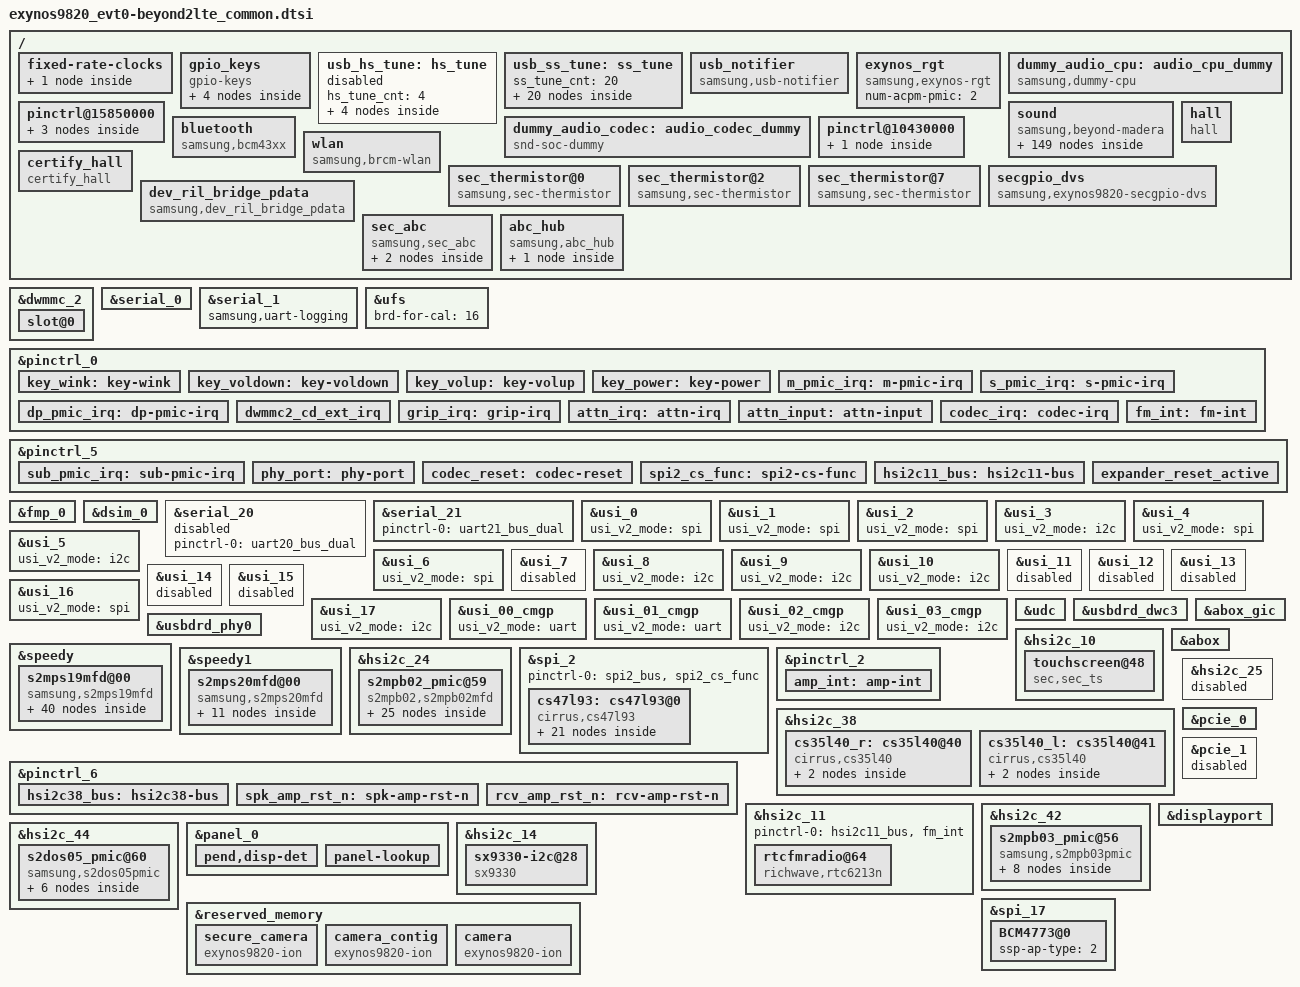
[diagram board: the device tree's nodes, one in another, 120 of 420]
/*
 * SAMSUNG EXYNOS9820 board device tree source
 *
 * Copyright (c) 2018 Samsung Electronics Co., Ltd.
 *		http://www.samsung.com
 *
 * This program is free software; you can redistribute it and/or modify
 * it under the terms of the GNU General Public License version 2 as
 * published by the Free Software Foundation.
*/
#include "exynos9820-beyond2lte_mst.dtsi"
#include "modem-s5000ap-sipc-pdata.dtsi"

/ {

	fragment@model {
		target-path = "/";
		__overlay__ {
			#address-cells = <2>;
			#size-cells = <1>;

			fixed-rate-clocks {
				oscclk {
					compatible = "samsung,exynos9820-oscclk";
					clock-frequency = <26000000>;
				};
			};

			gpio_keys {
				status = "okay";
				compatible = "gpio-keys";
				pinctrl-names = "default";
				pinctrl-0 = <&key_wink &key_voldown &key_volup &key_power>;
				button@1 {
					label = "gpio-keys: KEY_WINK";
					linux,code = <703>;
					gpios = <&gpa0 6 0xf>;
					gpio-key,wakeup = <1>;
				};
				button@2 {
					label = "gpio-keys: KEY_VOLUMEDOWN";
					linux,code = <114>;
					gpios = <&gpa0 4 0xf>;
				};
				button@3 {
					label = "gpio-keys: KEY_VOLUMEUP";
					linux,code = <115>;
					gpios = <&gpa0 3 0xf>;
				};
				button@4 {
					label = "gpio-keys: KEY_POWER";
					linux,code = <116>;
					gpios = <&gpa2 4 0xf>;
					gpio-key,wakeup = <1>;
				};
			};

			usb_hs_tune:hs_tune {
				status = "disabled";
				hs_tune_cnt = <4>;
				/* value = <device host> */
				hs_tune1 {
					tune_name = "tx_pre_emp";
					tune_value = <0x3 0x3>;
				};

				hs_tune2 {
					tune_name = "tx_vref";
					tune_value = <0xc 0xc>;
				};

				hs_tune3 {
					tune_name = "rx_sqrx";
					tune_value = <0x5 0x5>;
				};

				hs_tune4 {
					tune_name = "utmi_clk";
					tune_value = <0x1 0x1>;
				};
			};

			usb_ss_tune:ss_tune {
				status = "okay";
				ss_tune_cnt = <20>;
				/* value = <device host> */
				ss_tune1 {
					tune_name = "ssrx_sqhs_th";
					tune_value = <0x4 0x4>;
				};

				ss_tune2 {
					tune_name = "ssrx_lfps_th";
					tune_value = <0x2 0x2>;
				};

				ss_tune3 {
					tune_name = "ssrx_mf_eq_en";
					tune_value = <0x1 0x1>;
				};

				ss_tune4 {
					tune_name = "ssrx_mf_eq_ctrl_ss";
					tune_value = <0x6 0x6>;
				};

				ss_tune5 {
					tune_name = "ssrx_hf_eq_ctrl_ss";
					tune_value = <0xc 0xe>;
				};

				ss_tune6 {
					tune_name = "ssrx_mf_eq_ctrl_ssp";
					tune_value = <0x6 0x6>;
				};

				ss_tune7 {
					tune_name = "ssrx_hf_eq_ctrl_ssp";
					tune_value = <0xe 0xe>;
				};

				ss_tune8 {
					tune_name = "ssrx_dfe1_tap_ctrl";
					tune_value = <0x0 0x2>;
				};

				ss_tune9 {
					tune_name = "ssrx_dfe2_tap_ctrl";
					tune_value = <0x0 0x0>;
				};

				ss_tune10 {
					tune_name = "ssrx_dfe3_tap_ctrl";
					tune_value = <0x0 0x0>;
				};

				ss_tune11 {
					tune_name = "ssrx_dfe4_tap_ctrl";
					tune_value = <0x0 0x0>;
				};

				ss_tune12 {
					tune_name = "ssrx_dfe5_tap_ctrl";
					tune_value = <0x0 0x0>;
				};

				ss_tune13 {
					tune_name = "ssrx_term_cal";
					tune_value = <0xb 0xb>;
				};

				ss_tune14 {
					tune_name = "sstx_amp";
					tune_value = <0xb 0xb>;
				};

				ss_tune15 {
					tune_name = "sstx_deemp";
					tune_value = <0x5 0x5>;
				};

				ss_tune16 {
					tune_name = "sstx_pre_shoot";
					tune_value = <0x3 0x3>;
				};

				ss_tune17 {
					tune_name = "sstx_idrv_up";
					tune_value = <0x7 0x7>;
				};

				ss_tune18 {
					tune_name = "sstx_idrv_dn";
					tune_value = <0x0 0x0>;
				};

				ss_tune19 {
					tune_name = "sstx_up_term";
					tune_value = <0x3 0x3>;
				};

				ss_tune20 {
					tune_name = "sstx_dn_term";
					tune_value = <0x3 0x3>;
				};
			};

			usb_notifier {
				compatible = "samsung,usb-notifier";
				/*
				 * USB_LDOCONTROL_EXYNOS8895	1
				 * USB_LDOCONTROL_EXYNOS9810	2
				 * USB_LDOCONTROL_EXYNOS9820	3
				 */
				usb-ldocontrol = <3>;
				udc = <&udc>;
				disable_host_wakelock;
			};

			exynos_rgt {
				compatible = "samsung,exynos-rgt";
				num-acpm-pmic = <2>;
			};

			dummy_audio_codec: audio_codec_dummy {
				status = "okay";
				compatible = "snd-soc-dummy";
			};

			dummy_audio_cpu: audio_cpu_dummy {
				compatible = "samsung,dummy-cpu";
				status = "okay";
			};

			sound {
				status = "okay";
				compatible = "samsung,beyond-madera";

				clock-names = "xclkout";
				clocks = <&clock OSC_AUD>;

				cirrus,sysclk = <1 4 98304000>;
				cirrus,asyncclk = <2 5 98304000>;
				cirrus,dspclk = <8 4 147456000>;
				cirrus,outclk = <9 1 0>;
				cirrus,fll1-refclk = <1 0 26000000>;
				cirrus,fll2-refclk = <2 8 26000000>;

				cirrus,ampclk = <0 0 6144000>;

				samsung,routing = "DMIC1", "MICBIAS1A",
					"IN3L", "DMIC1",
					"DMIC2", "MICBIAS1B",
					"IN4L", "DMIC2",
					"HEADSETMIC", "MICBIAS2A",
					"IN1BL", "HEADSETMIC",
					"ABOX UAIF3 Capture", "BLUETOOTH MIC",
					"IN2BL", "FM IN",
					"IN2BR", "FM IN",
					"RECEIVER", "Left AMP SPK",
					"SPEAKER", "Right AMP SPK",
					"HEADPHONE", "HPOUT2L",
					"HEADPHONE", "HPOUT2R",
					"BLUETOOTH SPK", "ABOX UAIF3 Playback",
					"VTS PAD DPDM", "DMIC1",
					"VTS Input", "DMIC1";
				samsung,codec = <&abox &abox_uaif_0 &abox_uaif_1 &abox_uaif_2
					&abox_uaif_3 &abox_dsif &abox_rdma_0 &abox_rdma_1
					&abox_rdma_2 &abox_rdma_3 &abox_rdma_4 &abox_rdma_5
					&abox_rdma_6 &abox_rdma_7 &abox_rdma_8 &abox_rdma_9
					&abox_rdma_10 &abox_rdma_11 &abox_wdma_0 &abox_wdma_1
					&abox_wdma_2 &abox_wdma_3 &abox_wdma_4 &abox_wdma_5
					&abox_wdma_6 &abox_wdma_7 &cs35l40_l &cs35l40_r &vts>;
				samsung,prefix = "ABOX", "ABOX", "ABOX", "ABOX",
					"ABOX", "ABOX", "ABOX", "ABOX",
					"ABOX", "ABOX", "ABOX", "ABOX",
					"ABOX", "ABOX", "ABOX", "ABOX",
					"ABOX", "ABOX", "ABOX", "ABOX",
					"ABOX", "ABOX", "ABOX", "ABOX",
					"ABOX", "ABOX", "Left", "Right", "VTS";
				samsung,aux = <&abox_effect>;

				rdma0 {
					cpu {
						sound-dai = <&abox_rdma_0>;
					};
					platform {
						sound-dai = <&abox_rdma_0>;
					};
					codec {
						sound-dai = <&dummy_audio_codec>;
					};
				};
				rdma1 {
					cpu {
						sound-dai = <&abox_rdma_1>;
					};
					platform {
						sound-dai = <&abox_rdma_1>;
					};
					codec {
						sound-dai = <&dummy_audio_codec>;
					};
				};
				rdma2 {
					cpu {
						sound-dai = <&abox_rdma_2>;
					};
					platform {
						sound-dai = <&abox_rdma_2>;
					};
					codec {
						sound-dai = <&dummy_audio_codec>;
					};
				};
				rdma3 {
					cpu {
						sound-dai = <&abox_rdma_3>;
					};
					platform {
						sound-dai = <&abox_rdma_3>;
					};
					codec {
						sound-dai = <&dummy_audio_codec>;
					};
				};
				rdma4 {
					cpu {
						sound-dai = <&abox_rdma_4>;
					};
					platform {
						sound-dai = <&abox_rdma_4>;
					};
					codec {
						sound-dai = <&dummy_audio_codec>;
					};
				};
				rdma5 {
					cpu {
						sound-dai = <&abox_rdma_5>;
					};
					platform {
						sound-dai = <&abox_rdma_5>;
					};
					codec {
						sound-dai = <&dummy_audio_codec>;
					};
				};
				rdma6 {
					cpu {
						sound-dai = <&abox_rdma_6>;
					};
					platform {
						sound-dai = <&abox_rdma_6>;
					};
					codec {
						sound-dai = <&dummy_audio_codec>;
					};
				};
				rdma7 {
					cpu {
						sound-dai = <&abox_rdma_7>;
					};
					platform {
						sound-dai = <&abox_rdma_7>;
					};
					codec {
						sound-dai = <&dummy_audio_codec>;
					};
				};
				rdma8 {
					cpu {
						sound-dai = <&abox_rdma_8>;
					};
					platform {
						sound-dai = <&abox_rdma_8>;
					};
					codec {
						sound-dai = <&dummy_audio_codec>;
					};
				};
				rdma9 {
					cpu {
						sound-dai = <&abox_rdma_9>;
					};
					platform {
						sound-dai = <&abox_rdma_9>;
					};
					codec {
						sound-dai = <&dummy_audio_codec>;
					};
				};
				rdma10 {
					cpu {
						sound-dai = <&abox_rdma_10>;
					};
					platform {
						sound-dai = <&abox_rdma_10>;
					};
					codec {
						sound-dai = <&dummy_audio_codec>;
					};
				};
				rdma11 {
					cpu {
						sound-dai = <&abox_rdma_11>;
					};
					platform {
						sound-dai = <&abox_rdma_11>;
					};
					codec {
						sound-dai = <&dummy_audio_codec>;
					};
				};
				wdma0 {
					cpu {
						sound-dai = <&abox_wdma_0>;
					};
					platform {
						sound-dai = <&abox_wdma_0>;
					};
					codec {
						sound-dai = <&dummy_audio_codec>;
					};
				};
				wdma1 {
					cpu {
						sound-dai = <&abox_wdma_1>;
					};
					platform {
						sound-dai = <&abox_wdma_1>;
					};
					codec {
						sound-dai = <&dummy_audio_codec>;
					};
				};
				wdma2 {
					cpu {
						sound-dai = <&abox_wdma_2>;
					};
					platform {
						sound-dai = <&abox_wdma_2>;
					};
					codec {
						sound-dai = <&dummy_audio_codec>;
					};
				};
				wdma3 {
					cpu {
						sound-dai = <&abox_wdma_3>;
					};
					platform {
						sound-dai = <&abox_wdma_3>;
					};
					codec {
						sound-dai = <&dummy_audio_codec>;
					};
				};
				wdma4 {
					cpu {
						sound-dai = <&abox_wdma_4>;
					};
					platform {
						sound-dai = <&abox_wdma_4>;
					};
					codec {
						sound-dai = <&dummy_audio_codec>;
					};
				};
				wdma5 {
					cpu {
						sound-dai = <&abox_wdma_5>;
					};
					platform {
						sound-dai = <&abox_wdma_5>;
					};
					codec {
						sound-dai = <&dummy_audio_codec>;
					};
				};
				wdma6 {
					cpu {
						sound-dai = <&abox_wdma_6>;
					};
					platform {
						sound-dai = <&abox_wdma_6>;
					};
					codec {
						sound-dai = <&dummy_audio_codec>;
					};
				};
				wdma7 {
					cpu {
						sound-dai = <&abox_wdma_7>;
					};
					platform {
						sound-dai = <&abox_wdma_7>;
					};
					codec {
						sound-dai = <&dummy_audio_codec>;
					};
				};
				vts0 {
					cpu {
						sound-dai = <&vts 0>;
					};
					codec {
						sound-dai = <&dummy_audio_codec>;
					};
				};
				vts1 {
					cpu {
						sound-dai = <&vts 1>;
					};
					codec {
						sound-dai = <&dummy_audio_codec>;
					};
				};
				dp_audio {
					cpu {
						sound-dai = <&dummy_audio_cpu>;
					};
					codec {
						sound-dai = <&dummy_audio_codec>;
					};
				};
				uaif0 {
					format = "i2s";
					cpu {
						sound-dai = <&abox_uaif_0>;
					};
					codec {
						sound-dai = <&cs47l93 0>;
					};
				};
				uaif1 {
					format = "dsp_a";
					bitclock-inversion;
					cpu {
						sound-dai = <&abox_uaif_1>;
					};
					codec {
						sound-dai = <&cs35l40_l 0 &cs35l40_r 0>;
					};
				};
				uaif2 {
					format = "i2s";
					cpu {
						sound-dai = <&abox_uaif_2>;
					};
					codec {
						sound-dai = <&cs47l93 2>;
					};
				};
				uaif3 {
					format = "i2s";
					cpu {
						sound-dai = <&abox_uaif_3>;
					};
					codec {
						sound-dai = <&dummy_audio_codec>;
					};
				};
				dsif0 {
					format = "pdm";
					cpu {
						sound-dai = <&abox_dsif>;
					};
					codec {
						sound-dai = <&dummy_audio_codec>;
					};
				};
				sifs0 {
					cpu {
						sound-dai = <&abox 0>;
					};
					codec {
						sound-dai = <&dummy_audio_codec>;
					};
				};
				sifs1 {
					cpu {
						sound-dai = <&abox 1>;
					};
					codec {
						sound-dai = <&dummy_audio_codec>;
					};
				};
				sifs2 {
					cpu {
						sound-dai = <&abox 2>;
					};
					codec {
						sound-dai = <&dummy_audio_codec>;
					};
				};
				sifs3 {
					cpu {
						sound-dai = <&abox 3>;
					};
					codec {
						sound-dai = <&dummy_audio_codec>;
					};
				};
				sifs4 {
					cpu {
						sound-dai = <&abox 4>;
					};
					codec {
						sound-dai = <&dummy_audio_codec>;
					};
				};
				rsrc0 {
					cpu {
						sound-dai = <&abox 5>;
					};
					codec {
						sound-dai = <&dummy_audio_codec>;
					};
				};
				rsrc1 {
					cpu {
						sound-dai = <&abox 6>;
					};
					codec {
						sound-dai = <&dummy_audio_codec>;
					};
				};
				nsrc0 {
					cpu {
						sound-dai = <&abox 7>;
					};
					codec {
						sound-dai = <&dummy_audio_codec>;
					};
				};
				nsrc1 {
					cpu {
						sound-dai = <&abox 8>;
					};
					codec {
						sound-dai = <&dummy_audio_codec>;
					};
				};
				nsrc2 {
					cpu {
						sound-dai = <&abox 9>;
					};
					codec {
						sound-dai = <&dummy_audio_codec>;
					};
				};
				nsrc3 {
					cpu {
						sound-dai = <&abox 10>;
					};
					codec {
						sound-dai = <&dummy_audio_codec>;
					};
				};
				nsrc4 {
					cpu {
						sound-dai = <&abox 11>;
					};
					codec {
						sound-dai = <&dummy_audio_codec>;
					};
				};
				nsrc5 {
					cpu {
						sound-dai = <&abox 12>;
					};
					codec {
						sound-dai = <&dummy_audio_codec>;
					};
				};
				nsrc6 {
					cpu {
						sound-dai = <&abox 13>;
					};
					codec {
						sound-dai = <&dummy_audio_codec>;
					};
				};
				debug-trace@1 {
					cpu {
						sound-dai = <&cs47l93 6>;
					};
					codec {
						sound-dai = <&cs47l93 7>;
					};
				};
			};
			pinctrl@15850000 {
				bt_hostwake: bt-hostwake {
					samsung,pins = "gpa2-3";
					samsung,pin-function = <0>;
					samsung,pin-pud = <0>;
				};

				hall_irq: hall-irq {
					samsung,pins = "gpa3-6";
					samsung,pin-function = <0xf>;
					samsung,pin-pud = <0>;
					samsung,pin-drv = <0>;
				};

				certify_hall_irq: certify-hall-irq {
					samsung,pins = "gpa0-2";
					samsung,pin-function = <0xf>;
					samsung,pin-pud = <0>;
					samsung,pin-drv = <0>;
				};
			};

			pinctrl@10430000 {
				bt_btwake: bt-btwake {
					samsung,pins = "gpg2-0";
					samsung,pin-function = <1>;
					samsung,pin-pud = <0>;
					samsung,pin-con-pdn = <3>;
					samsung,pin-pud-pdn = <0>;
				};
			};

			bluetooth {
				compatible = "samsung,bcm43xx";
				gpios = <&expander_gpios 7 0    /*BT_EN*/
				&gpg2 0 0    /*BT_WAKE*/
				&gpa2 3 0xF    /*BT_HOST_WAKE*/ >;
				pinctrl-names = "default";
				pinctrl-0=<&bt_hostwake &bt_btwake>;
				status = "okay";
			};

			wlan {
				compatible = "samsung,brcm-wlan";
				gpios = <&gpg0 5 0x1 /* WLAN_EN */
						&gpa0 7 0x1 /* WLAN HOST WAKE GPIO_0 */>;
				pinctrl-names = "default";
				pinctrl-0 = <&cfg_wlanen &wlan_host_wake>;
				status = "okay";
			};

			hall {
				status = "okay";
				compatible = "hall";
				pinctrl-names = "default";
				pinctrl-0 = <&hall_irq>;
				hall,gpio_flip_cover = <&gpa3 6 0>;
			};

			certify_hall {
				status = "okay";
				compatible = "certify_hall";
				pinctrl-names = "default";
				pinctrl-0 = <&certify_hall_irq>;
				certify_hall,gpio_certify_cover = <&gpa0 2 0>;
			};

			sec_thermistor@0 {
				compatible = "samsung,sec-thermistor";
				status = "okay";
				thermistor_name = "sec-ap-thermistor";
				id = <0>;

				adc_array = <275 324 380 450 528 619 729 856 1003 1161
					  1345 1545 1766 1980 2222 2457 2685 2901 3102 3279
					  3426 3551 3659>;
				temp_array = <900 850 800 750 700 650 600 550 500 450
					  400 350 300 250 200 150 100 50 0 (-50)
					  (-100) (-150) (-200)>;

				io-channels = <&exynos_adc 0>;
				io-channel-names = "adc-ap-temp";
				io-channel-ranges;
			};

			sec_thermistor@2 {
				compatible = "samsung,sec-thermistor";
				status = "okay";
				thermistor_name = "sec-wf-thermistor";
				id = <1>;

				adc_array = <275 324 380 450 528 619 729 856 1003 1161
					  1345 1545 1766 1980 2222 2457 2685 2901 3102 3279
					  3426 3551 3659>;
				temp_array = <900 850 800 750 700 650 600 550 500 450
					  400 350 300 250 200 150 100 50 0 (-50)
					  (-100) (-150) (-200)>;

				io-channels = <&exynos_adc 2>;
				io-channel-names = "adc-wf-temp";
				io-channel-ranges;
			};

			sec_thermistor@7 {
				compatible = "samsung,sec-thermistor";
				status = "okay";
				thermistor_name = "sec-pa-thermistor";
				id = <2>;

				adc_array = <327 347 367 388 410 433 456 482 507 534
					562 591 621 651 684 717 750 786 821 858
					896 935 975 1016 1057 1100 1143 1187 1231 1277
					1323 1369 1416 1463 1511 1559 1608 1657 1706 1755
					1804 1853 1902 1951 2000 2048 2096 2144 2192 2239
					2285 2332 2378 2421 2467 2510 2553 2596 2637 2678
					2719 2758 2797 2833 2872 2906 2942 2976 3011 3042
					3074 3106 3136 3165 3195 3222 3249 3277 3302 3327
					3352 3375 3397 3420 3441 3461 3482 3502 3520 3538
					3557 3573 3591 3607 3620 3636 3650 3666 3680 3691
					3705 3716 3730 3741 3752 3761 3773 3782 3793 3802
					3812>;

				temp_array =
					<(-200) (-190) (-180) (-170) (-160) (-150) (-140) (-130) (-120) (-110)
					(-100) (-90) (-80) (-70) (-60) (-50) (-40) (-30) (-20) (-10)
					0 10 20 30 40 50 60 70 80 90
					100 110 120 130 140 150 160 170 180 190
					200 210 220 230 240 250 260 270 280 290
					300 310 320 330 340 350 360 370 380 390
					400 410 420 430 440 450 460 470 480 490
					500 510 520 530 540 550 560 570 580 590
					600 610 620 630 640 650 660 670 680 690
					700 710 720 730 740 750 760 770 780 790
					800 810 820 830 840 850 860 870 880 890
					900>;

				io-channels = <&exynos_adc 7>;
				io-channel-names = "adc-pa-temp";
				io-channel-ranges;
			};

			secgpio_dvs {
				compatible = "samsung,exynos9820-secgpio-dvs";
				status = "okay";
			};

			dev_ril_bridge_pdata {
				compatible = "samsung,dev_ril_bridge_pdata";
				status = "okay";
			};

			sec_abc {
				compatible = "samsung,sec_abc";
				status = "okay";

				gpu {
					gpu,label="GPU fault";
					gpu,threshold_count=<20>;
					gpu,threshold_time=<1200>;
				};
				aicl {
					aicl,label="battery aicl";
					aicl,threshold_count=<5>;
					aicl,threshold_time=<300>;
				};
			};

			abc_hub {
				compatible = "samsung,abc_hub";
				status = "okay";

				bootc {
					bootc,time_spec_user = <100000>; /* user binary user build */
					bootc,time_spec_eng = <100000>; /* user binary eng build */
					bootc,time_spec_fac = <100000>; /* factory binary */
				};
			};
		}; /* end of __overlay__ */
	}; /* end of fragment */
}; /* end of root */

&dwmmc_2 {
	#address-cells = <1>;
	#size-cells = <0>;
	status = "okay";
	num-slots = <1>;
	supports-4bit;
	supports-cmd23;
	supports-erase;
	supports-highspeed;
	sd-uhs-sdr50;
	sd-uhs-sdr104;
	card-detect-gpio;
	bypass-for-allpass;
	use-fine-tuning;
	card-init-hwacg-ctrl;
	skip-init-mmc-scan;
	qos-dvfs-level = <400000>;
	fifo-depth = <0x40>;
	desc-size = <4>;
	card-detect-delay = <200>;
	samsung,dw-mshc-ciu-div = <3>;
	clock-frequency = <800000000>;
	samsung,dw-mshc-sdr-timing = <3 0 2 0>;
	samsung,dw-mshc-ddr-timing = <3 0 2 1>;
	samsung,dw-mshc-sdr50-timing = <3 0 4 2>;
	samsung,dw-mshc-sdr104-timing = <3 0 3 0>;

	num-ref-clks = <9>;
	ciu_clkin = <25 50 50 25 50 100 200 50 50>;

	/* Swapping clock drive strength */
	clk-drive-number = <6>;
	pinctrl-names = "default",
		"fast-slew-rate-1x",
		"fast-slew-rate-1_5x",
		"fast-slew-rate-2x",
		"fast-slew-rate-2_5x",
		"fast-slew-rate-3x",
		"fast-slew-rate-4x",
		"pins-as-pdn",
		"pins-as-func";
	pinctrl-0 = <&sd2_clk &sd2_cmd &sd2_bus1 &sd2_bus4 &dwmmc2_cd_ext_irq>;
	pinctrl-1 = <&sd2_clk_fast_slew_rate_1x>;
	pinctrl-2 = <&sd2_clk_fast_slew_rate_1_5x>;
	pinctrl-3 = <&sd2_clk_fast_slew_rate_2x>;
	pinctrl-4 = <&sd2_clk_fast_slew_rate_2_5x>;
	pinctrl-5 = <&sd2_clk_fast_slew_rate_3x>;
	pinctrl-6 = <&sd2_clk_fast_slew_rate_4x>;
	pinctrl-7 = <&sd2_pins_as_pdn>;
	pinctrl-8 = <&sd2_clk &sd2_cmd &sd2_bus1 &sd2_bus4>;

	card-detect = <&gpa1 5 0xf>;
	sec-sd-slot-type = <2>; /* Hybrid Tray SD slot */

	slot@0 {
		reg = <0>;
		bus-width = <4>;
		disable-wp;
	};
};


&serial_0 {
	status = "okay";
};

&serial_1 {
	samsung,uart-logging;
	status = "okay";
};

&ufs {
	/* board type for UFS CAL */
	brd-for-cal = /bits/ 8 <16>;  /* (1:SMDK, 16:UNIV) board */
};

&pinctrl_0 {
	key_wink: key-wink {
		samsung,pins = "gpa0-6";
		samsung,pin-function = <0xf>;
		samsung,pin-pud = <0>;
		samsung,pin-drv = <0>;
	};

	key_voldown: key-voldown {
		samsung,pins = "gpa0-4";
		samsung,pin-function = <0xf>;
		samsung,pin-pud = <0>;
		samsung,pin-drv = <0>;
	};

	key_volup: key-volup {
		samsung,pins = "gpa0-3";
		samsung,pin-function = <0xf>;
		samsung,pin-pud = <0>;
		samsung,pin-drv = <0>;
	};

	key_power: key-power {
		samsung,pins = "gpa2-4";
		samsung,pin-function = <0xf>;
	};

	m_pmic_irq: m-pmic-irq {
		samsung,pins = "gpa0-1";
		samsung,pin-pud = <3>;
		samsung,pin-drv = <3>;
	};

	s_pmic_irq: s-pmic-irq {
		samsung,pins = "gpa2-5";
		samsung,pin-pud = <3>;
		samsung,pin-drv = <3>;
	};

	dp_pmic_irq: dp-pmic-irq {
		samsung,pins = "gpa1-4";
		samsung,pin-function = <0>;
		samsung,pin-pud = <0>;
		samsung,pin-drv = <0>;
	};

	dwmmc2_cd_ext_irq: dwmmc2_cd_ext_irq {
		samsung,pins = "gpa1-5";
		samsung,pin-function = <0xf>;
		samsung,pin-pud = <0>;
		samsung,pin-drv = <4>;
	};

	grip_irq: grip-irq {
		samsung,pins = "gpa3-0";
		samsung,pin-function = <0xf>;
		samsung,pin-pud = <0>;
		samsung,pin-drv = <3>;
	};
};

&pinctrl_5 {
	sub_pmic_irq: sub-pmic-irq {
		samsung,pins = "gpg2-1";
		samsung,pin-function = <0>;
		samsung,pin-pud = <0>;
		samsung,pin-drv = <0>;
	};
};

&fmp_0 {
	exynos,block-type = "sda";
	exynos,fips-block_offset = <5>;
};

&dsim_0 {
	lcd_info = <&s6e3ha9_beyond2>;
	/* reset, power */
	gpios = <&gpa3 4 0x1>;
};

&serial_20 {
	pinctrl-names = "default";
	pinctrl-0 = <&uart20_bus_dual>;
	status = "disabled";
};

&serial_21 {
	pinctrl-names = "default";
	pinctrl-0 = <&uart21_bus_dual>;
	status = "okay";
};

&usi_0 {
	usi_v2_mode = "spi";
	status = "okay";
};

&usi_1 {
	usi_v2_mode = "spi";
	status = "okay";
};

&usi_2 {
	usi_v2_mode = "spi";
	status = "okay";
};

&usi_3 {
	usi_v2_mode = "i2c";
	status = "okay";
};

&usi_4 {
	usi_v2_mode = "spi";
	status = "okay";
};

&usi_5 {
	usi_v2_mode = "i2c";
	status = "okay";
};

&usi_6 {
	usi_v2_mode = "spi";
	status = "okay";
};

&usi_7 {
	status = "disabled";
};

&usi_8 {
	usi_v2_mode = "i2c";
	status = "okay";
};

&usi_9 {
	usi_v2_mode = "i2c";
	status = "okay";
};

&usi_10 {
	usi_v2_mode = "i2c";
	status = "okay";
};

&usi_11 {
	status = "disabled";
};

&usi_12 {
	status = "disabled";
};

&usi_13 {
	status = "disabled";
};

&usi_14 {
	status = "disabled";
};

&usi_15 {
	status = "disabled";
};

&usi_16 {
	usi_v2_mode = "spi";
	status = "okay";
};

&usi_17 {
	usi_v2_mode = "i2c";
	status = "okay";
};

&usi_00_cmgp {
	usi_v2_mode = "uart";
	status = "okay";
};

&usi_01_cmgp {
	usi_v2_mode = "uart";
	status = "okay";
};

&usi_02_cmgp {
	usi_v2_mode = "i2c";
	status = "okay";
};

&usi_03_cmgp {
	usi_v2_mode = "i2c";
	status = "okay";
};

&pinctrl_5 {
	phy_port: phy-port {
		samsung,pins = "gpg0-4";
		samsung,pin-function = <0x0>;
		samsung,pin-pud = <3>;
		samsung,pin-drv = <0>;
	};
};

&udc {
	status = "okay";
};

&usbdrd_dwc3 {
	dr_mode = "otg";
	maximum-speed = "super-speed-plus";
	snps,quirk-frame-length-adjustment = <0x20>;
	snps,u1u2_exitfail_quirk;
	/* ux_exit_in_px should be defined in MK, LT */
	snps,ux_exit_in_px_quirk;
	/* elastic_buf_mode_quirk should be defined in MK */
	snps,elastic_buf_mode_quirk;
	usb3-lpm-capable;
	snps,usb3_lpm_capable;
	snps,has-lpm-erratum;
	snps,lpm-nyet-threshold = <0>;
	adj-sof-accuracy = <1>;
	/*
	 * dis-u2-freeclk-exists-quirk, dis_u2_susphy_quirk are alternative.
	 * One of them should be selected
	 */
	snps,dis-u2-freeclk-exists-quirk;
	/*snps,dis_u2_susphy_quirk;*/

	usb_audio_offloading = <1>;
	abox = <&abox>; /* Temporary block */
};

&usbdrd_phy0 {
	status = "okay";

	pinctrl-names = "default";
	pinctrl-0 = <&phy_port>;
 	phy,gpio_phy_port = <&gpg0 4 0x0>;
	reverse_con_dir = <1>;
	hs_tune_param = <&usb_hs_tune>;
	ss_tune_param = <&usb_ss_tune>;
};

&pinctrl_0 {
	attn_irq: attn-irq {
		samsung,pins = "gpa1-0";
		samsung,pin-function = <0xf>;
		samsung,pin-pud = <0>;
		samsung,pin-drv = <0>;
	};

	attn_input: attn-input {
		samsung,pins = "gpa1-0";
		samsung,pin-function = <0>;
		samsung,pin-pud = <1>;
	};
};

&hsi2c_10 {
	#address-cells = <1>;
	#size-cells = <0>;
	status = "okay";
	samsung,reset-before-trans;
	samsung,stop-after-trans;	/* LSI IC ONLY */
	touchscreen@48 {
		compatible = "sec,sec_ts";
		reg = <0x48>;
		pinctrl-names = "on_state", "off_state";
		pinctrl-0 = <&attn_irq>;
		pinctrl-1 = <&attn_input>;
		sec,irq_gpio = <&gpa1 0 0>;
		sec,irq_type = <8200>;
		sec,max_coords = <4096 4096>;
//		sec,area-size = <133 266 341>; /* indicator: 24dp navigator:48dp edge:60px dpi=320 */
		sec,mis_cal_check = <1>;
		sec,regulator_dvdd = "tsp_io";
		sec,regulator_avdd = "tsp_avdd";
		sec,regulator_boot_on;
		sec,tclm_level = <1>;
		sec,firmware_name = "tsp_sec/y771_crown.bin";
		sec,project_name = "BEYOND2", "G975";
		support_fod;
		support_dex_mode;
		sec,factory_item_version = <1>;
		sec,bringup = <2>;
	};
};

&speedy {
	#address-cells = <1>;
	#size-cells = <0>;
	status = "okay";
	s2mps19mfd@00 {
		compatible = "samsung,s2mps19mfd";
		acpm-ipc-channel = <2>;
		acpm-speedy-channel = <0>;
		i2c-speedy-address;
		s2mps19,wakeup = "enabled";
		s2mps19,irq-gpio = <&gpa0 1 0>;
		reg = <0x00>;
		interrupts = <2 0 0>;
		interrupt-parent = <&gpa0>;
		pinctrl-names = "default";
		pinctrl-0 = <&m_pmic_irq &smpl_warn>;
		gpios = <&gpp3 4 0>;
		smpl_warn_en = <1>; /* 1 : enable , 0 : disable */
		/* range of smpl_warn_vth */
		/* 0x00 : 2.1V, 0x20 : 2.3V, 0x40 : 2.5V, 0x60 : 2.7V 0x80 : 2.9V */
		/* 0xA0 : 3.1V, 0xC0 : 3.3V, 0xE0 : 3.5V */
		smpl_warn_vth = <0xA0>;
		/* LowBat_Hys[4:3] 00(100mV), 01(200mV), 10(300mV), 11(400mV) */
		smpl_warn_hys = <0x00>;
		ocp_warn1_en = <0>; /* 1 : enable, 0 : disable */
		ocp_warn1_cnt = <0>; /* ocp warn reset timing control, 0 : 2 clock, 1 : 32 clock */
		ocp_warn1_dvs_mask = <0>; /* ocp warn mask when dvs, 0 : not masked, 1 : masked  */
		ocp_warn1_lv = <0x0>; /* step : -250mA */
		ocp_warn2_en = <0>; /* 1 : enable, 0 : disable */
		ocp_warn2_cnt = <0>; /* ocp warn reset timing control, 0 : 2 clock, 1 : 32 clock */
		ocp_warn2_dvs_mask = <0>; /* ocp warn mask when dvs, 0 : not masked, 1 : masked  */
		ocp_warn2_lv = <0x0>; /* step : -250mA */
		adc_mode = <1>; /* 0 : disable, 1 : current meter, 2 : power meter */
		adc_sync_mode = <2>; /* 1 : sync mode, 2 : async mode */
		/* RTC: wtsr/smpl */
		wtsr_en = "enabled"; /* enable */
		smpl_en = "enabled"; /* enable */
		wtsr_timer_val = <3>;	/* 1000ms */
		smpl_timer_val = <2>;	/* 300ms */
		sub_smpl_en = "enabled"; /* enable */
		check_jigon = <0>; /* do not check jigon */
		/* RTC: If it's first boot, reset rtc to 1/1/2017 12:00:00(Sun) */
		init_time,sec = <0>;
		init_time,min = <0>;
		init_time,hour = <12>;
		init_time,mday = <1>;
		init_time,mon = <0>;
		init_time,year = <117>;
		init_time,wday = <0>;

		regulators {
			buck1_reg: BUCK1M {
				regulator-name = "m_vdd_buck1";
				regulator-min-microvolt = <450000>;
				regulator-max-microvolt = <1100000>;
				regulator-always-on;
				regulator-ramp-delay = <6000>;
				regulator-initial-mode = <2>;
			};

			buck2_reg: BUCK2M {
				regulator-name = "m_vdd_buck2";
				regulator-min-microvolt = <450000>;
				regulator-max-microvolt = <1300000>;
				regulator-always-on;
				regulator-ramp-delay = <6000>;
				regulator-initial-mode = <2>;
			};

			buck3_reg: BUCK3M {
				regulator-name = "m_vdd_buck3";
				regulator-min-microvolt = <450000>;
				regulator-max-microvolt = <1300000>;
				regulator-always-on;
				regulator-ramp-delay = <6000>;
				regulator-initial-mode = <1>;
			};

			buck4_reg: BUCK4M {
				regulator-name = "m_vdd_buck4";
				regulator-min-microvolt = <450000>;
				regulator-max-microvolt = <1300000>;
				regulator-always-on;
				regulator-ramp-delay = <6000>;
				regulator-initial-mode = <1>;
			};

			buck5_reg: BUCK5M {
				regulator-name = "m_vdd_buck5";
				regulator-min-microvolt = <450000>;
				regulator-max-microvolt = <950000>;
				regulator-always-on;
				regulator-ramp-delay = <6000>;
				regulator-initial-mode = <2>;
			};

			buck6_reg: BUCK6M {
				regulator-name = "m_vdd_buck6";
				regulator-min-microvolt = <450000>;
				regulator-max-microvolt = <1100000>;
				regulator-always-on;
				regulator-ramp-delay = <6000>;
				regulator-initial-mode = <2>;
			};

			buck7_reg: BUCK7M {
				regulator-name = "m_vdd_buck7";
				regulator-min-microvolt = <450000>;
				regulator-max-microvolt = <1300000>;
				regulator-always-on;
				regulator-ramp-delay = <6000>;
				regulator-initial-mode = <2>;
			};

			buck8_reg: BUCK8M {
				regulator-name = "m_vdd_buck8";
				regulator-min-microvolt = <450000>;
				regulator-max-microvolt = <950000>;
				regulator-always-on;
				regulator-ramp-delay = <6000>;
				regulator-initial-mode = <2>;
			};

			buck9_reg: BUCK9M {
				regulator-name = "m_vdd_buck9";
				regulator-min-microvolt = <750000>;
				regulator-max-microvolt = <1150000>;
				regulator-always-on;
				regulator-ramp-delay = <6000>;
				regulator-initial-mode = <3>;
			};

			buck10_reg: BUCK10M {
				regulator-name = "m_vdd_buck10";
				regulator-min-microvolt = <900000>;
				regulator-max-microvolt = <1300000>;
				regulator-always-on;
				regulator-ramp-delay = <6000>;
				regulator-initial-mode = <3>;
			};

			buck11_reg: BUCK11M {
				regulator-name = "m_vdd_buck11";
				regulator-min-microvolt = <1100000>;
				regulator-max-microvolt = <1500000>;
				regulator-always-on;
				regulator-ramp-delay = <6000>;
				regulator-initial-mode = <3>;
			};

			buck12_reg: BUCK12M {
				regulator-name = "m_vdd_buck12";
				regulator-min-microvolt = <1700000>;
				regulator-max-microvolt = <2150000>;
				regulator-always-on;
				regulator-ramp-delay = <6000>;
				regulator-initial-mode = <3>;
			};

			ldo1_reg: LDO1M {
				regulator-name = "m_vdd_ldo1";
				regulator-min-microvolt = <700000>;
				regulator-max-microvolt = <950000>;
				regulator-always-on;
				regulator-ramp-delay = <12000>;
				regulator-initial-mode = <3>;
			};

			ldo2_reg: LDO2M {
				regulator-name = "vqmmc";
				regulator-min-microvolt = <1700000>;
				regulator-max-microvolt = <3300000>;
				regulator-ramp-delay = <12000>;
				regulator-initial-mode = <3>;
			};

			ldo3_reg: LDO3M {
				regulator-name = "m_vdd_ldo3";
				regulator-min-microvolt = <700000>;
				regulator-max-microvolt = <1100000>;
				regulator-always-on;
				regulator-ramp-delay = <12000>;
				regulator-initial-mode = <1>;
			};

			ldo4_reg: LDO4M {
				regulator-name = "m_vdd_ldo4";
				regulator-min-microvolt = <1600000>;
				regulator-max-microvolt = <1950000>;
				regulator-always-on;
				regulator-ramp-delay = <12000>;
				regulator-initial-mode = <1>;
			};

			ldo5_reg: LDO5M {
				regulator-name = "m_vdd_ldo5";
				regulator-min-microvolt = <450000>;
				regulator-max-microvolt = <1100000>;
				regulator-always-on;
				regulator-ramp-delay = <12000>;
				regulator-initial-mode = <1>;
			};

			ldo6_reg: LDO6M {
				regulator-name = "m_vdd_ldo6";
				regulator-min-microvolt = <450000>;
				regulator-max-microvolt = <950000>;
				regulator-always-on;
				regulator-ramp-delay = <12000>;
				regulator-initial-mode = <1>;
			};

			ldo7_reg: LDO7M {
				regulator-name = "m_vdd_ldo7";
				regulator-min-microvolt = <450000>;
				regulator-max-microvolt = <1100000>;
				regulator-always-on;
				regulator-ramp-delay = <12000>;
				regulator-initial-mode = <1>;
			};

			ldo8_reg: LDO8M {
				regulator-name = "m_vdd_ldo8";
				regulator-min-microvolt = <450000>;
				regulator-max-microvolt = <1300000>;
				regulator-always-on;
				regulator-ramp-delay = <12000>;
				regulator-initial-mode = <1>;
			};

			ldo9_reg: LDO9M {
				regulator-name = "m_vdd_ldo9";
				regulator-min-microvolt = <700000>;
				regulator-max-microvolt = <1300000>;
				regulator-always-on;
				regulator-ramp-delay = <12000>;
				regulator-initial-mode = <1>;
			};

			ldo10_reg: LDO10M {
				regulator-name = "m_vdd_ldo10";
				regulator-min-microvolt = <700000>;
				regulator-max-microvolt = <1100000>;
				regulator-boot-on;
				regulator-ramp-delay = <12000>;
				regulator-initial-mode = <3>;
			};

			ldo11_reg: LDO11M {
				regulator-name = "m_vdd_ldo11";
				regulator-min-microvolt = <1600000>;
				regulator-max-microvolt = <1950000>;
				regulator-boot-on;
				regulator-ramp-delay = <12000>;
				regulator-initial-mode = <3>;
			};

			ldo12_reg: LDO12M {
				regulator-name = "m_vdd_ldo12";
				regulator-min-microvolt = <1700000>;
				regulator-max-microvolt = <3350000>;
				regulator-boot-on;
				regulator-ramp-delay = <12000>;
				regulator-initial-mode = <3>;
			};

			ldo15_reg: LDO15M {
				regulator-name = "vmmc";
				regulator-min-microvolt = <2500000>;
				regulator-max-microvolt = <3300000>;
				regulator-ramp-delay = <12000>;
				regulator-initial-mode = <3>;
			};

			ldo16_reg: LDO16M {
				regulator-name = "m_vdd_ldo16";
				regulator-min-microvolt = <2500000>;
				regulator-max-microvolt = <3300000>;
				regulator-always-on;
				regulator-ramp-delay = <12000>;
				regulator-initial-mode = <3>;
			};

			ldo17_reg: LDO17M {
				regulator-name = "vdd_pmic_codec_1p8";
				regulator-min-microvolt = <1800000>;
				regulator-max-microvolt = <1800000>;
				regulator-always-on;
				regulator-initial-mode = <3>;
				regulator-boot-on;
			};

			ldo18_reg: LDO18M {
				regulator-name = "vdd_codec_1p2";
				regulator-min-microvolt = <1200000>;
				regulator-max-microvolt = <1200000>;
				regulator-ramp-delay = <12000>;
				regulator-enable-ramp-delay = <5000>;
				regulator-initial-mode = <3>;
			};

			ldo19_reg: LDO19M {
				regulator-name = "tsp_io";
				regulator-min-microvolt = <1800000>;
				regulator-max-microvolt = <1800000>;
				regulator-always-on;
				regulator-ramp-delay = <12000>;
				regulator-initial-mode = <2>;
			};

			ldo20_reg: LDO20M {
				regulator-name = "m_vdd_ldo20";
				regulator-min-microvolt = <2500000>;
				regulator-max-microvolt = <3300000>;
				regulator-always-on;
				regulator-ramp-delay = <12000>;
				regulator-initial-mode = <3>;
			};

			ldo21_reg: LDO21M {
				regulator-name = "vdd_mcu_1p8";
				regulator-min-microvolt = <1800000>;
				regulator-max-microvolt = <1800000>;
				regulator-always-on;
				regulator-ramp-delay = <12000>;
				regulator-initial-mode = <3>;
			};

			ldo22_reg: LDO22M {
				regulator-name = "VDD_NFC_1P8";
				regulator-min-microvolt = <1800000>;
				regulator-max-microvolt = <1800000>;
				regulator-ramp-delay = <12000>;
				regulator-initial-mode = <2>;
			};

			ldo23_reg: LDO23M {
				regulator-name = "VDDD_1.2V_FRONTSUB";
				regulator-min-microvolt = <1200000>;
				regulator-max-microvolt = <1200000>;
				regulator-ramp-delay = <12000>;
				regulator-initial-mode = <3>;
			};

			ldo24_reg: LDO24M {
				regulator-name = "VDDA_2.8V_FRONTSUB";
				regulator-min-microvolt = <2800000>;
				regulator-max-microvolt = <2800000>;
				regulator-ramp-delay = <12000>;
				regulator-initial-mode = <3>;
			};

			ldo25_reg: LDO25M {
				regulator-name = "VDDIO_1.8V_FRONTSUB";
				regulator-min-microvolt = <1800000>;
				regulator-max-microvolt = <1800000>;
				regulator-ramp-delay = <12000>;
				regulator-initial-mode = <3>;
			};

			ldo26_reg: LDO26M {
				regulator-name = "m_vdd_ldo26";
				regulator-min-microvolt = <1600000>;
				regulator-max-microvolt = <2200000>;
				regulator-always-on;
				regulator-ramp-delay = <12000>;
				regulator-initial-mode = <3>;
			};

			ldo27_reg: LDO27M {
				regulator-name = "tsp_avdd";
				regulator-min-microvolt = <3000000>;
				regulator-max-microvolt = <3000000>;
				regulator-boot-on;
				regulator-ramp-delay = <12000>;
				regulator-initial-mode = <3>;
			};

			ldo28_reg: LDO28M {
				regulator-name = "VDD_ESE_1P8";
				regulator-min-microvolt = <1800000>;
				regulator-max-microvolt = <1800000>;
				regulator-ramp-delay = <12000>;
				regulator-initial-mode = <2>;
			};

			ldo29_reg: LDO29M {
				regulator-name = "vdd-fm-2p8";
				regulator-min-microvolt = <2800000>;
				regulator-max-microvolt = <2800000>;
				regulator-always-on;
				regulator-ramp-delay = <12000>;
				regulator-initial-mode = <3>;
			};
		};
	};
};

&speedy1 {
	#address-cells = <1>;
	#size-cells = <0>;
	status = "okay";
	s2mps20mfd@00 {
		compatible = "samsung,s2mps20mfd";
		acpm-ipc-channel = <2>;
		acpm-speedy-channel = <1>;
		i2c-speedy-address;
		s2mps20,wakeup = "enabled";
		s2mps20,irq-gpio = <&gpa2 5 0>;
		reg = <0x00>;
		interrupts = <1 0 0>;
		interrupt-parent = <&gpa2>;
		pinctrl-names = "default";
		pinctrl-0 = <&s_pmic_irq>;
		adc_mode = <1>; /* 0 : disable, 1 : current meter, 2 : power meter */
		adc_sync_mode = <2>; /* 1 : sync mode, 2 : async mode */
		ocp_warn3_en = <0>; /* 1 : enable, 0 : disable */
		ocp_warn3_cnt = <0>; /* ocp warn reset timing control, 0 : 2 clock, 1 : 32 clock */
		ocp_warn3_dvs_mask = <0>; /* ocp warn mask when dvs, 0 : not masked, 1 : masked  */
		ocp_warn3_lv = <0x0>; /* step : -250mA */

		regulators {
			s_buck1_reg: BUCK1S {
				regulator-name = "s_vdd_buck1";
				regulator-min-microvolt = <450000>;
				regulator-max-microvolt = <950000>;
				regulator-always-on;
				regulator-ramp-delay = <6000>;
				regulator-initial-mode = <2>;
			};

			s_buck2_reg: BUCK2S {
				regulator-name = "s_vdd_buck2";
				regulator-min-microvolt = <900000>;
				regulator-max-microvolt = <1300000>;
				regulator-always-on;
				regulator-ramp-delay = <6000>;
				regulator-initial-mode = <3>;
			};

			s_ldo1_reg: LDO1S {
				regulator-name = "s_vdd_ldo1";
				regulator-min-microvolt = <450000>;
				regulator-max-microvolt = <950000>;
				regulator-always-on;
				regulator-ramp-delay = <12000>;
				regulator-initial-mode = <1>;
			};

			s_ldo2_reg: LDO2S {
				regulator-name = "s_vdd_ldo2";
				regulator-min-microvolt = <1600000>;
				regulator-max-microvolt = <1950000>;
				regulator-always-on;
				regulator-ramp-delay = <12000>;
				regulator-initial-mode = <3>;
			};

			s_ldo7_reg: LDO7S {
				regulator-name = "s_vdd_ldo7";
				regulator-min-microvolt = <1600000>;
				regulator-max-microvolt = <1950000>;
				regulator-always-on;
				regulator-ramp-delay = <12000>;
				regulator-initial-mode = <3>;
			};

			s_ldo8_reg: LDO8S {
				regulator-name = "s_vdd_ldo8";
				regulator-min-microvolt = <700000>;
				regulator-max-microvolt = <1100000>;
				regulator-always-on;
				regulator-ramp-delay = <12000>;
				regulator-initial-mode = <3>;
			};

			s_ldo9_reg: LDO9S {
				regulator-name = "s_vdd_ldo9";
				regulator-min-microvolt = <700000>;
				regulator-max-microvolt = <1100000>;
				regulator-always-on;
				regulator-ramp-delay = <12000>;
				regulator-initial-mode = <3>;
			};

			s_ldo10_reg: LDO10S {
				regulator-name = "s_vdd_ldo10";
				regulator-min-microvolt = <1600000>;
				regulator-max-microvolt = <1950000>;
				regulator-always-on;
				regulator-ramp-delay = <12000>;
				regulator-initial-mode = <3>;
			};

			s_ldo11_reg: LDO11S {
				regulator-name = "s_vdd_ldo11";
				regulator-min-microvolt = <1600000>;
				regulator-max-microvolt = <1950000>;
				regulator-always-on;
				regulator-ramp-delay = <12000>;
				regulator-initial-mode = <3>;
			};

			s_ldo12_reg: LDO12S {
				regulator-name = "s_vdd_ldo12";
				regulator-min-microvolt = <1700000>;
				regulator-max-microvolt = <3350000>;
				regulator-always-on;
				regulator-ramp-delay = <12000>;
				regulator-initial-mode = <3>;
			};
		};
	};
};

&hsi2c_24 {
	#address-cells = <1>;
	#size-cells = <0>;
	status = "okay";
	s2mpb02_pmic@59 {
		compatible = "s2mpb02,s2mpb02mfd";
		reg = <0x59>;

		s2mpb02,wakeup;
		pinctrl-names = "default";
		pinctrl-0 = <&sub_pmic_irq>;

		regulators {
			_buck1_reg: s2mpb02-buck1 {
				regulator-name = "S2MPB02_BUCK1";
				regulator-min-microvolt = <1300000>;
				regulator-max-microvolt = <1300000>;
				regulator-always-on;
				regulator-boot-on;
			};

			_buck2_reg: s2mpb02-buck2 {
				regulator-name = "S2MPB02_BUCK2";
				regulator-min-microvolt = <1300000>;
				regulator-max-microvolt = <1300000>;
				regulator-always-on;
				regulator-boot-on;
			};

			_buckboost_reg: s2mpb02-bb {
				regulator-name = "S2MPB02_BB";
				regulator-min-microvolt = <2600000>;
				regulator-max-microvolt = <4000000>;
				regulator-always-on;
				regulator-boot-on;
			};

			_ldo1_reg: s2mpb02-ldo1 {
				regulator-name = "S2MPB02_LDO1";
				regulator-min-microvolt = <600000>;
				regulator-max-microvolt = <600000>;
			};

			_ldo2_reg: s2mpb02-ldo2 {
				regulator-name = "S2MPB02_LDO2";
				regulator-min-microvolt = <600000>;
				regulator-max-microvolt = <600000>;
			};

			_ldo3_reg: s2mpb02-ldo3 {
				regulator-name = "VDDD_1.05V_SUB";
				regulator-min-microvolt = <1050000>;
				regulator-max-microvolt = <1050000>;
			};

			_ldo4_reg: s2mpb02-ldo4 {
				regulator-name = "VDDD_1.05V_WIDESUB";
				regulator-min-microvolt = <1050000>;
				regulator-max-microvolt = <1050000>;
			};

			_ldo5_reg: s2mpb02-ldo5 {
				regulator-name = "VDDD_1.05V_VT";
				regulator-min-microvolt = <1050000>;
				regulator-max-microvolt = <1050000>;
			};

			_ldo6_reg: s2mpb02-ldo6 {
				regulator-name = "VDDIO_1.8V_VT";
				regulator-min-microvolt = <1800000>;
				regulator-max-microvolt = <1800000>;
			};

			_ldo7_reg: s2mpb02-ldo7 {
				regulator-name = "VDDIO_1.8V_SUB";
				regulator-min-microvolt = <1800000>;
				regulator-max-microvolt = <1800000>;
			};

			_ldo8_reg: s2mpb02-ldo8 {
				regulator-name = "VDDIO_1.8V_WIDESUB";
				regulator-min-microvolt = <1800000>;
				regulator-max-microvolt = <1800000>;
			};

			_ldo9_reg: s2mpb02-ldo9 {
				regulator-name = "S2MPB02_LDO9";
				regulator-min-microvolt = <600000>;
				regulator-max-microvolt = <600000>;
			};

			_ldo10_reg: s2mpb02-ldo10 {
				regulator-name = "VDDD_1.8V_OIS";
				regulator-min-microvolt = <1800000>;
				regulator-max-microvolt = <1800000>;
				regulator-always-on;
			};

			_ldo11_reg: s2mpb02-ldo11 {
				regulator-name = "VDDA_2.8V_SUB";
				regulator-min-microvolt = <2800000>;
				regulator-max-microvolt = <2800000>;
			};

			_ldo12_reg: s2mpb02-ldo12 {
				regulator-name = "VDDAF_2.8V_SUB";
				regulator-min-microvolt = <2800000>;
				regulator-max-microvolt = <2800000>;
			};

			_ldo13_reg: s2mpb02-ldo13 {
				regulator-name = "VDDA_2.95V_VT";
				regulator-min-microvolt = <2950000>;
				regulator-max-microvolt = <2950000>;
			};

			_ldo14_reg: s2mpb02-ldo14 {
				regulator-name = "VDDAF_COMMON_CAM";
				regulator-min-microvolt = <3300000>;
				regulator-max-microvolt = <3300000>;
			};

			_ldo15_reg: s2mpb02-ldo15 {
				regulator-name = "VDDA_2.8V_WIDESUB";
				regulator-min-microvolt = <2800000>;
				regulator-max-microvolt = <2800000>;
			};

			_ldo16_reg: s2mpb02-ldo16 {
				regulator-name = "VDDAF_2.8V_VT";
				regulator-min-microvolt = <2800000>;
				regulator-max-microvolt = <2800000>;
			};

			_ldo17_reg: s2mpb02-ldo17 {
				regulator-name = "VDD_GRIP_3P3";
				regulator-min-microvolt = <2800000>;
				regulator-max-microvolt = <3000000>;
				regulator-always-on;
				regulator-boot-on;
			};

			_ldo18_reg: s2mpb02-ldo18 {
				regulator-name = "S2MPB02_LDO18";
				regulator-min-microvolt = <3300000>;
				regulator-max-microvolt = <3375000>;
			};
		};

		torch {
			torch1-gpio = <&gpg2 4 0x1>;
			flash1-gpio = <&gpg3 6 0x1>;

			status = "okay";

			leds1 {
				ledname = "leds-sec1";
				id = <0>;
				brightness = <0xC>; /* Nx100+50 : 1250mA */
				timeout = <0x7>; /* (N+1)x62.5 : 500ms */
				torch_table_enable = <0>;
			};

			leds2 {
				ledname = "torch-sec1";
				id = <1>;
				brightness = <0xC>; /* (n+1)x20 = 260mA */
				timeout = <0xF>;
				torch_table_enable = <1>;
				torch_table = <2 4 4 5 6 8 9 10 10 12>;
			};
		};
	};
};

&abox_gic {
	status = "okay";
};

&abox {
	status = "okay";
};

&pinctrl_0 {
	codec_irq: codec-irq {
		samsung,pins = "gpa2-2";
		samsung,pin-function = <0xf>;
		samsung,pin-pud = <0>;
		samsung,pin-con-pdn =<3>;
		samsung,pin-pud-pdn = <0>;
	};
};

&pinctrl_5 {
	codec_reset: codec-reset {
		samsung,pins ="gpg1-0";
		samsung,pin-function = <1>;
		samsung,pin-pud = <0>;
		samsung,pin-con-pdn =<3>;
		samsung,pin-pud-pdn = <0>;
	};

	spi2_cs_func: spi2-cs-func {
		samsung,pins = "gpp0-7";
		samsung,pin-function = <2>;
		samsung,pin-pud = <3>;
		samsung,pin-drv = <0>;
	};
};

&spi_2 {
	#address-cells = <1>;
	#size-cells = <0>;
	status = "okay";
	pinctrl-names = "default";
	pinctrl-0 = <&spi2_bus &spi2_cs_func>;

	cs47l93: cs47l93@0 {
		compatible = "cirrus,cs47l93";
		reg = <0x0>;

		spi-max-frequency = <25000000>;

		interrupts = <2 0 0>;
		interrupt-controller;
		#interrupt-cells = <2>;
		interrupt-parent = <&gpa2>;
		gpio-controller;
		#gpio-cells = <2>;
		#sound-dai-cells = <1>;

		AVDD-supply = <&ldo17_reg>;
		DBVDD1-supply = <&ldo17_reg>;
		CPVDD1-supply = <&ldo17_reg>;
		CPVDD2-supply = <&ldo18_reg>;
		DCVDD-supply = <&ldo18_reg>;

		reset-gpios = <&gpg1 0 0>;

		cirrus,dmic-ref = <0 0 1 1>;
		cirrus,inmode = <
			0 0 0 0 /* IN1 */
			0 0 1 1 /* IN2 */
		>;
		cirrus,out-mono = <0 0 0 1 0 0>;
		cirrus,auxpdm-falling-edge;

		pinctrl-names = "probe", "active";
		pinctrl-0 = <&codec_reset &codec_irq>;
		pinctrl-1 = <&cs47l93_defaults>;

		cirrus,gpsw = <3 0>;

		madera_pinctrl: madera-pinctrl {
			compatible = "cirrus,madera-pinctrl";

			cs47l93_defaults: cs47l93-gpio-defaults {
				aif1 {
					groups = "aif1";
					function = "aif1";
					bias-bus-hold;
				};

				gpio9 {
					groups = "gpio9";
					function = "io";
					bias-disable;
					drive-strength = <8>;
				};

				gpio10 {
					groups = "gpio10";
					function = "io";
					bias-disable;
					drive-strength = <8>;
				};

				aif3 {
					groups = "aif3";
					function = "aif3";
					bias-bus-hold;
				};
			};
		};

		micvdd {
			regulator-min-microvolt = <3000000>;
			regulator-max-microvolt = <3000000>;
		};

		MICBIAS1 {
			regulator-min-microvolt = <1800000>;
			regulator-max-microvolt = <1800000>;
			cirrus,ext-cap = <1>;
		};
		MICBIAS1A {
			regulator-active-discharge = <1>;
		};
		MICBIAS1B {
			regulator-active-discharge = <1>;
		};
		MICBIAS1C {
			regulator-active-discharge = <1>;
		};
		MICBIAS1D {
			regulator-active-discharge = <1>;
		};
		MICBIAS2 {
			regulator-min-microvolt = <2800000>;
			regulator-max-microvolt = <2800000>;
			cirrus,ext-cap = <1>;
			regulator-soft-start;
		};
		MICBIAS2A {
			regulator-active-discharge = <1>;
		};

		cirrus,accdet {
			#address-cells = <1>;
			#size-cells = <0>;

			acc@1 {
				reg = <2>;

				cirrus,micd-bias-start-time = <0x1>;
				cirrus,micd-rate = <7>;
				cirrus,micd-detect-debounce-ms = <300>;
				cirrus,micd-clamp-mode = <0x8>;
				cirrus,jd-use-jd2;
				cirrus,hs-mic = <1>;

				cirrus,init-delay-ms = <30>;
				cirrus,micd-dbtime = <0x1>;
				cirrus,micd-timeout-ms = <1000>;
				cirrus,micd-force-micbias;
				cirrus,hpdet-short-circuit-imp = <2>;
				cirrus,hpdet-ext-res = <3300>;
				cirrus,micd-ranges = <
					116 226
					173 582
					321 115
					752 114
					1257 217
				>;
				cirrus,micd-software-compare;
				cirrus,micd-open-circuit-declare = <1>;
				cirrus,jd-wake-time = <5000>;

				cirrus,moisture-pin = <7>;
				cirrus,moisture-imp = <2000>;
				cirrus,moisture-debounce = <100>;

				cirrus,micd-configs = <
					0 1 4 0 1
				>;
				cirrus,hpd-pins = <2 5 0 0>;
			};
		};

		adsps {
			#address-cells = <1>;
			#size-cells = <0>;

			adsp@0FFE00 {
				reg = <0x0FFE00>;
				firmware {
					TRACE {
						cirrus,full-name;
						cirrus,wmfw-file = "cs47l93-dsp1-trace.wmfw";
						cirrus,bin-file = "None";
						cirrus,compr-caps = <1 8 0x4 1 8000 16000 24000 32000 48000>;
					};
				};
			};
		};

		controller-data {
			samsung,spi-feedback-delay = <1>;
			samsung,spi-chip-select-mode = <0>;
		};
	};
};

&pinctrl_6 {
	hsi2c38_bus: hsi2c38-bus {
		samsung,pins = "gph0-6", "gph0-7";
		samsung,pin-function = <3>;
		samsung,pin-pud = <0>;
		samsung,pin-drv = <0>;
		samsung,pin-pud-pdn = <0>;
	};
	spk_amp_rst_n: spk-amp-rst-n {
		samsung,pins ="gph1-1";
		samsung,pin-function = <1>;
		samsung,pin-val = <0>;
		samsung,pin-pud = <0>;
		samsung,pin-con-pdn =<3>;
		samsung,pin-pud-pdn = <0>;
	};
	rcv_amp_rst_n: rcv-amp-rst-n {
		samsung,pins ="gph1-2";
		samsung,pin-function = <1>;
		samsung,pin-val = <0>;
		samsung,pin-pud = <0>;
		samsung,pin-con-pdn =<3>;
		samsung,pin-pud-pdn = <0>;
	};
};

&pinctrl_2 {
	amp_int: amp-int {
		samsung,pins = "gpm24-0";
		samsung,pin-function = <0xf>;
		samsung,pin-pud = <0>;
		samsung,pin-con-pdn =<3>;
		samsung,pin-pud-pdn = <0>;
	};
};

&hsi2c_38 {
	#address-cells = <1>;
	#size-cells = <0>;
	status = "okay";
	clock-frequency = <400000>;

	pinctrl-names = "default";
	pinctrl-0 = <&hsi2c38_bus &spk_amp_rst_n &rcv_amp_rst_n &amp_int>;

	cs35l40_r: cs35l40@40 {
		#sound-dai-cells = <1>;
		compatible = "cirrus,cs35l40";
		reg = <0x40>;

		interrupt-parent = <&gpm24>;
		interrupts = <0 0 0>;

		reset-gpios = <&gph1 1 0>;

		cirrus,right-channel-amp;
		cirrus,dsp-part-name = "cs35l40-bot";
		cirrus,asp-sdout-hiz = <0x3>;

		cirrus,hw-noise-gate-select = <0x3F>;
		cirrus,hw-noise-gate-delay = <0x0>;
		cirrus,hw-noise-gate-threshold = <0x6>;

		cirrus,boost-peak-milliamp = <4100>;

		cirrus,classh-internal-algo {
			cirrus,classh-headroom = <0xb>;
			cirrus,classh-release-rate = <0x4>;
			cirrus,classh-mem-depth = <0x5>;
			cirrus,classh-wk-fet-delay = <0x4>;
			cirrus,classh-wk-fet-thld = <0x1>;
		};

		cirrus,gpio-config2 {
			cirrus,gpio-src-select = <0x4>;
			cirrus,gpio-output-enable;
		};
	};

	cs35l40_l: cs35l40@41 {
		#sound-dai-cells = <1>;
		compatible = "cirrus,cs35l40";
		reg = <0x41>;

		interrupt-parent = <&gpm24>;
		interrupts = <0 0 0>;

		reset-gpios = <&gph1 2 0>;

		cirrus,dsp-part-name = "cs35l40-rcv";
		cirrus,asp-sdout-hiz = <0x3>;

		cirrus,hw-noise-gate-select = <0x3F>;
		cirrus,hw-noise-gate-delay = <0x0>;
		cirrus,hw-noise-gate-threshold = <0x6>;

		cirrus,boost-peak-milliamp = <4100>;

		cirrus,classh-internal-algo {
			cirrus,classh-headroom = <0xb>;
			cirrus,classh-release-rate = <0x4>;
			cirrus,classh-mem-depth = <0x5>;
			cirrus,classh-wk-fet-delay = <0x4>;
			cirrus,classh-wk-fet-thld = <0x1>;
		};

		cirrus,gpio-config2 {
			cirrus,gpio-src-select = <0x4>;
			cirrus,gpio-output-enable;
		};
	};
};

&pinctrl_0 {
	fm_int: fm-int {
		samsung,pins = "gpa2-1";
		samsung,pin-function = <0xf>;
		samsung,pin-pud = <0>;
		samsung,pin-con-pdn =<3>;
		samsung,pin-pud-pdn = <0>;
	};
};

&pinctrl_5 {
	hsi2c11_bus: hsi2c11-bus {
		samsung,pins = "gpp1-6", "gpp1-7";
		samsung,pin-function = <3>;
		samsung,pin-pud = <0>;
		samsung,pin-drv = <0>;
		samsung,pin-pud-pdn = <0>;
	};
};

&hsi2c_11 {
	status = "okay";
	pinctrl-names = "default";
	pinctrl-0 = <&hsi2c11_bus &fm_int>;

	rtcfmradio@64 {
		compatible = "richwave,rtc6213n", "rtc6213n";
		reg = <0x64>;
		interrupts = <1 0 0>;
		interrupt-parent = <&gpa2>;
		fmint-gpio = <&gpa2 1 0>;
		volume_db;
		radio_vol = <44 43 39 36 33 30 27 24 21 18 15 12 10 8 6 4>;
	};
};

&hsi2c_42 {
	#address-cells = <1>;
	#size-cells = <0>;
	status = "okay";
	s2mpb03_pmic@56 {
		compatible = "samsung,s2mpb03pmic";
		reg = <0x56>;

		s2mpb03,wakeup;

		regulators {
			__ldo1_reg: s2mpb03-ldo1 {
				regulator-name = "VDDD_1.0V_CAM";
				regulator-min-microvolt = <1025000>;
				regulator-max-microvolt = <1025000>;
			};

			__ldo2_reg: s2mpb03-ldo2 {
				regulator-name = "VDDQ_1.1V_CAM";
				regulator-min-microvolt = <1100000>;
				regulator-max-microvolt = <1100000>;
			};

			__ldo3_reg: s2mpb03-ldo3 {
				regulator-name = "VDDIO_1.8V_CAM";
				regulator-min-microvolt = <1800000>;
				regulator-max-microvolt = <1800000>;
			};

			__ldo4_reg: s2mpb03-ldo4 {
				regulator-name = "VDDD_RET_1.0V_CAM";
				regulator-min-microvolt = <700000>;
				regulator-max-microvolt = <1025000>;
			};

			__ldo5_reg: s2mpb03-ldo5 {
				regulator-name = "VDDA_2.4V_CAM";
				regulator-min-microvolt = <2400000>;
				regulator-max-microvolt = <2400000>;
			};

			__ldo6_reg: s2mpb03-ldo6 {
				regulator-name = "VDDA_2.8V_CAM";
				regulator-min-microvolt = <2800000>;
				regulator-max-microvolt = <2800000>;
			};

			__ldo7_reg: s2mpb03-ldo7 {
				regulator-name = "VDD_VM_2.8V_OIS";
				regulator-min-microvolt = <2800000>;
				regulator-max-microvolt = <2800000>;
			};
		};
	};
};

&hsi2c_44 {
	#address-cells = <1>;
	#size-cells = <0>;
	status = "okay";
	s2dos05_pmic@60 {
		compatible = "samsung,s2dos05pmic";
		reg = <0x60>;
		s2dos05,wakeup;
		pinctrl-names = "default";
		pinctrl-0 = <&dp_pmic_irq>;
		s2dos05,s2dos05_int = <&gpa1 4 0>;
		adc_mode = <1>; /* 0 : disable, 1 : current meter, 2 : power meter */
		adc_sync_mode = <2>; /* 1 : sync mode, 2 : async mode */
		regulators {
			dp_buck: s2dos05-buck1 {
				regulator-name = "vdd1";
				regulator-min-microvolt = <1500000>;
				regulator-max-microvolt = <1600000>;
				regulator-boot-on;
			};
			dp_ldo1: s2dos05-ldo1 {
				regulator-name = "vdd2";
				regulator-min-microvolt = <1800000>;
				regulator-max-microvolt = <1800000>;
				regulator-boot-on;
			};
			dp_ldo2: s2dos05-ldo2 {
				regulator-name = "vdd3";
				regulator-min-microvolt = <1500000>;
				regulator-max-microvolt = <2000000>;
				regulator-always-on;
				regulator-boot-on;
			};
			dp_ldo3: s2dos05-ldo3{
				regulator-name = "vdd4";
				regulator-min-microvolt = <2700000>;
				regulator-max-microvolt = <3775000>;
				regulator-always-on;
				regulator-boot-on;
			};
			dp_ldo4: s2dos05-ldo4{
				regulator-name = "vdd5";
				regulator-min-microvolt = <3000000>;
				regulator-max-microvolt = <3000000>;
				regulator-boot-on;
			};
		};
	};
};

/***** reference symbol node *****/
&pinctrl_5 {
expander_reset_active: expander_reset_active {
	       samsung,pins = "gpg4-0";
	       samsung,pin-function = <1>;
	       samsung,pin-pud = <0>;
	       samsung,pin-val = <1>;
       };
};

&hsi2c_25 {
	#address-cells = <1>;
	#size-cells = <0>;
	status = "disabled";
};

&pcie_0 {
	pinctrl-names = "default","idle";
	pinctrl-0 = <&pcie0_clkreq &pcie0_perst &pcie_wake &cfg_wlanen &wlan_host_wake>;
	pinctrl-1 = <&pcie0_perst &pcie_wake &cfg_wlanen &wlan_host_wake>;
	status = "okay";
	use-sysmmu = "true";
	use-cache-coherency = "true";
	use-msi = "false";
	ep-device-type = <EP_BCM_WIFI>;
};

&pcie_1 {
	status = "disabled";
	use-sysmmu = "false";
	use-cache-coherency = "true";
	use-msi = "false";
};

&displayport {
	status = "okay";
	dp,aux_sw_oe = <&expander_gpios 4 0>;
	dp,sbu_sw_sel = <&expander_gpios 1 0>;
	dp,usb_con_sel = <&gpg0 4 0>;

	pinctrl-names = "default";
};

&panel_0 {

    status = "okay";

	ddi_info = <&s6e3ha9_beyond2>;
	gpio,lcd-reset = <&gpa3 4 0x1>;
	gpio,disp-det = <&gpg2 2 0x0>;

	regulator,3p0 = "vdd5";
	regulator,1p8 = "vdd2";
	regulator,1p6 = "vdd1";

	#address-cells = <2>;
	#size-cells = <1>;
	ranges;

	pend,disp-det {
		reg = <0x0 0x10430A08 0x4>;
		pend-bit = <0x2>;
	};

	panel-lookup {
		panel-name = "s6e3ha9_beyond2_a3_s0_default", "s6e3ha9_beyond2_a3_s0_utype", "s6e3ha9_beyond2_a3_s0_preliminary";
		panel-ddi-info = <&s6e3ha9_beyond2 &s6e3ha9_beyond1_1440x2960>;
		panel-lut = <
			0x000000 0x300000 0x2 0x1  /* S6E3HA9 1440x2960 TEMPORARY PANEL */
			0x100000 0x300000 0x2 0x0  /* S6E3HA9 1440x3040 L-Cut PANEL */
			0x000000 0x0F0000 0x1 0x0  /* S6E3HA9 1440x3040 U-Type PANEL */

			/* default panel */
			0x000000 0x000000 0x0 0x0  /* S6E3HA9 1440x3040 PANEL */
		>;
	};
};

&hsi2c_14 {
	gpios = <&gpp2 4 0 &gpp2 5 0>;
	clock-frequency = <400000>;
	status = "okay";

	#address-cells = <1>;
	#size-cells = <0>;

	sx9330-i2c@28 {
		compatible = "sx9330";
		reg = <0x28>;
		status = "okay";
		pinctrl-names = "default";
		pinctrl-0 = <&grip_irq>;
		interrupt-parent = <&gpa3>;
		interrupts = <0 0 0>;

		sx9330,nirq-gpio = <&gpa3 0 0>;

		sx9330,afeparamsph1_reg = <0x00000E27>;  /* PH1 RINT : Lowest, Again : 4.95pF, Freq : 125khz */
		sx9330,adcfiltph1_reg = <0x00227F10>;    /* Threshold : 8064.5, ADCFILTSAMPLES : 1 */
		sx9330,avgbfilt_reg = <0x00000C80>;      /* AVGPOSFILT : 1/256, AVGNEGFILT : 1/2 */
	};
};

&reserved_memory {
	secure_camera {
		compatible = "exynos9820-ion";
		ion,heapname = "secure_camera_heap";
		reg = <0x0 0x96000000 0x2200000>;
		ion,secure;
		ion,protection_id = <11>;
		ion,alignment = <0x10000>;
	};
	camera_contig {
		compatible = "exynos9820-ion";
		ion,heapname = "camera_contig_heap";
		reg = <0x0 0x98200000 0xE00000>;
		ion,secure;
		ion,protection_id = <10>;
	};
	camera {
		compatible = "exynos9820-ion";
		ion,heapname = "camera_heap";
		reg = <0x0 0x99000000 0x1B800000>;
		ion,recyclable;
	};
};

&spi_17 {
        BCM4773@0 {
        	ssp-ap-type = <2>;
        };
};

&speedy {
	s2mps19mfd@00 {
		smpl_warn_dev2= <0>;
	};
};
